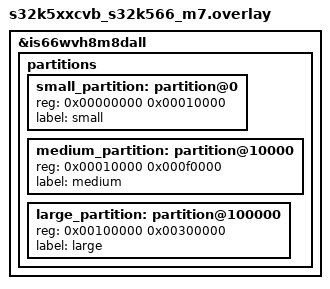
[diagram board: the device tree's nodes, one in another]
/*
 * Copyright 2025 NXP
 *
 * SPDX-License-Identifier: Apache-2.0
 */

/delete-node/ &storage_partition;

&is66wvh8m8dall {
	partitions {
		small_partition: partition@0 {
			reg = <0x00000000 0x00010000>;
			label = "small";
		};

		medium_partition: partition@10000 {
			reg = <0x00010000 0x000f0000>;
			label = "medium";
		};

		large_partition: partition@100000 {
			reg = <0x00100000 0x00300000>;
			label = "large";
		};
	};
};
